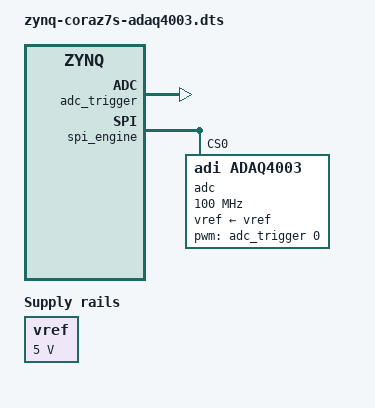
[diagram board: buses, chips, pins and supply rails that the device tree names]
// SPDX-License-Identifier: GPL-2.0
/*
 * Analog Devices ADAQ4003
 *
 * hdl_project: <pulsar_adc/coraz7s>
 * Link: https://github.com/analogdevicesinc/hdl/tree/main/projects/pulsar_adc
 * board_revision: <A>
 *
 * Copyright (C) 2023 Analog Devices Inc.
 */
/dts-v1/;
#include "zynq-coraz7s.dtsi"
#include <dt-bindings/interrupt-controller/irq.h>
#include <dt-bindings/gpio/gpio.h>

/ {
	vref: regulator-vref {
		compatible = "regulator-fixed";
		regulator-name = "fixed-supply";
		regulator-min-microvolt = <5000000>;
		regulator-max-microvolt = <5000000>;
		regulator-always-on;
	};
};

&fpga_axi {

		adc_trigger: pwm@0x44b00000 {
		compatible = "adi,axi-pwmgen";
		reg = <0x44b00000 0x1000>;
		label = "adc_conversion_trigger";
		#pwm-cells = <2>;
		clocks = <&spi_clk>;
	};

	spi_engine: spi@44a00000 {
		compatible = "adi,axi-spi-engine-1.00.a";
		reg = <0x44a00000 0x10000>;
		interrupt-parent = <&intc>;
		interrupts = <0 56 IRQ_TYPE_LEVEL_HIGH>;
		clocks = <&clkc 15 &spi_clk>;
		clock-names = "s_axi_aclk", "spi_clk";
		num-cs = <1>;

		#address-cells = <0x1>;
		#size-cells = <0x0>;

		adc@0 {
			compatible = "adi,adaq4003";
			reg = <0>;
			spi-max-frequency = <100000000>;
			clocks = <&spi_clk>;
			clock-names = "ref_clk";
			dmas = <&rx_dma 0>;
			dma-names = "rx";
			pwms = <&adc_trigger 0 0>;
			pwm-names = "cnv";
			vref-supply = <&vref>;
			adi,high-z-input;
			adi,gain-milli = /bits/ 16 <454>;

			#address-cells = <1>;
			#size-cells = <0>;

			channel@0 {
				reg = <0>;
				diff-channels = <0 1>;
			};
		};
	};

	rx_dma: rx-dmac@44a30000 {
		compatible = "adi,axi-dmac-1.00.a";
		reg = <0x44a30000 0x1000>;
		#dma-cells = <1>;
		interrupt-parent = <&intc>;
		interrupts = <0 57 IRQ_TYPE_LEVEL_HIGH>;
		clocks = <&clkc 16>;

		adi,channels {
			#size-cells = <0>;
			#address-cells = <1>;

			dma-channel@0 {
				reg = <0>;
				adi,source-bus-width = <32>;
				adi,source-bus-type = <1>;
				adi,destination-bus-width = <64>;
				adi,destination-bus-type = <0>;
			};
		};
	};

	spi_clk: axi-clkgen@0x44a70000 {
		compatible = "adi,axi-clkgen-2.00.a";
		reg = <0x44a70000 0x10000>;
		#clock-cells = <0>;
		clocks = <&clkc 15>, <&clkc 15>;
		clock-names = "s_axi_aclk", "clkin1";
		clock-output-names = "spi_clk";
	};
};
